# WBZ450 register map
Vendor: Microchip
Registers are 32-bit, read-write, reset 0x0 unless marked. A register's access mark holds for its fields unless they carry their own. Addresses are absolute, and some are shared; only a register's first bit layout is shown; [hi:lo] are bit positions; 'fields as' and 'values as' point back to an identical list.

## TC3
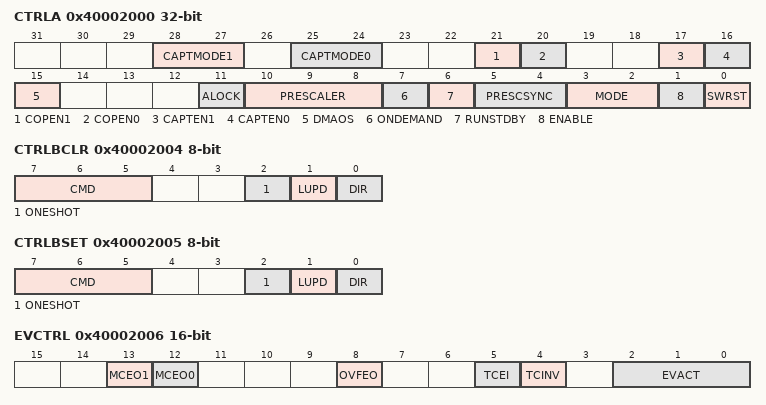
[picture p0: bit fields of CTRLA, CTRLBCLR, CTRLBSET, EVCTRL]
0x40002000 CTRLA
  [28:27] CAPTMODE1 — Capture mode Channel 1
    0=DEFAULT (Default capture); 1=CAPTMIN (Minimum capture); 2=CAPTMAX (Maximum capture)
  [25:24] CAPTMODE0 — Capture Mode Channel 0
    values as CAPTMODE1
  [21] COPEN1 — Capture On Pin 1 Enable
  [20] COPEN0 — Capture On Pin 0 Enable
  [17] CAPTEN1 — Capture Channel 1 Enable
  [16] CAPTEN0 — Capture Channel 0 Enable
  [15] DMAOS — DMA One Shot
  [11] ALOCK — Auto Lock
  [10:8] PRESCALER
    0=DIV1 (Prescaler: GCLK_TC); 1=DIV2 (Prescaler: GCLK_TC/2); 2=DIV4 (Prescaler: GCLK_TC/4); 3=DIV8 (Prescaler: GCLK_TC/8); 4=DIV16 (Prescaler: GCLK_TC/16); 5=DIV64 (Prescaler: GCLK_TC/64); 6=DIV256 (Prescaler: GCLK_TC/256); 7=DIV1024 (Prescaler: GCLK_TC/1024)
  [7] ONDEMAND — Clock On Demand
  [6] RUNSTDBY — Run during Standby
  [5:4] PRESCSYNC — Prescaler and Counter Synchronization
    0=GCLK (Reload or reset the counter on next generic clock); 1=PRESC (Reload or reset the counter on next prescaler clock); 2=RESYNC (Reload or reset the counter on next generic clock and reset the prescaler counter)
  [3:2] MODE — Timer Counter Mode
    0=COUNT16 (Counter in 16-bit mode); 1=COUNT8 (Counter in 8-bit mode); 2=COUNT32 (Counter in 32-bit mode)
  [1] ENABLE
  [0] SWRST — Software Reset
0x40002004 CTRLBCLR 8-bit
  [7:5] CMD — Command
    0=NONE (No action); 1=RETRIGGER (Force a start, restart or retrigger); 2=STOP (Force a stop); 3=UPDATE (Force update of double-buffered register); 4=READSYNC (Force a read synchronization of COUNT); 5=DMAOS (One-shot DMA trigger)
  [2] ONESHOT — One-Shot on Counter
  [1] LUPD — Lock Update
  [0] DIR — Counter Direction
0x40002005 CTRLBSET 8-bit
  fields as CTRLBCLR
0x40002006 EVCTRL 16-bit
  [13] MCEO1 — MC Event Output Enable 1
  [12] MCEO0 — MC Event Output Enable 0
  [8] OVFEO — Event Output Enable
  [5] TCEI — TC Event Enable
  [4] TCINV — TC Event Input Polarity
  [2:0] EVACT — Event Action
    0=OFF (Event action disabled); 1=RETRIGGER (Start, restart or retrigger TC on event); 2=COUNT (Count on event); 3=START (Start TC on event); 4=STAMP (Time stamp capture); 5=PPW (Period catured in CC0, pulse width in CC1); 6=PWP (Period catured in CC1, pulse width in CC0); 7=PW (Pulse width capture)
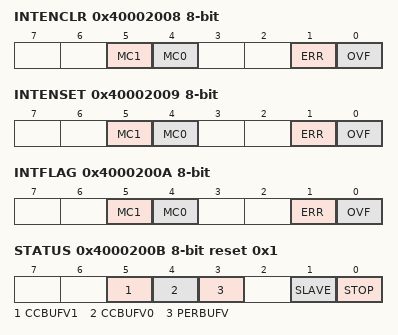
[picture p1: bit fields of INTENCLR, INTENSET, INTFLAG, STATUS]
0x40002008 INTENCLR 8-bit
  [5] MC1 — MC Interrupt Disable 1
  [4] MC0 — MC Interrupt Disable 0
  [1] ERR — ERR Interrupt Disable
  [0] OVF — OVF Interrupt Disable
0x40002009 INTENSET 8-bit
  [5] MC1 — MC Interrupt Enable 1
  [4] MC0 — MC Interrupt Enable 0
  [1] ERR — ERR Interrupt Enable
  [0] OVF — OVF Interrupt Enable
0x4000200A INTFLAG 8-bit
  [5] MC1 — MC Interrupt Flag 1
  [4] MC0 — MC Interrupt Flag 0
  [1] ERR — ERR Interrupt Flag
  [0] OVF — OVF Interrupt Flag
0x4000200B STATUS 8-bit reset 0x1
  [5] CCBUFV1 — Compare channel buffer 1 valid
  [4] CCBUFV0 — Compare channel buffer 0 valid
  [3] PERBUFV — Synchronization Busy Status
  [1] SLAVE — Slave Status Flag
  [0] STOP — Stop Status Flag
0x4000200C WAVE 8-bit
  [1:0] WAVEGEN — Waveform Generation Mode
    0=NFRQ (Normal frequency); 1=MFRQ (Match frequency); 2=NPWM (Normal PWM); 3=MPWM (Match PWM)
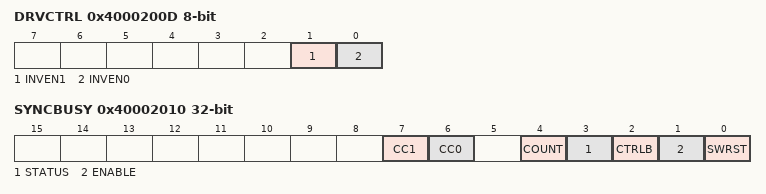
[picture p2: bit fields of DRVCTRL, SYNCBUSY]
0x4000200D DRVCTRL 8-bit
  [1] INVEN1 — Output Waveform Invert Enable 1
  [0] INVEN0 — Output Waveform Invert Enable 0
0x4000200F DBGCTRL 8-bit
  [0] DBGRUN — Run During Debug
0x40002010 SYNCBUSY ro
  [7] CC1 — Compare Channel 1
  [6] CC0 — Compare Channel 0
  [4] COUNT — Counter
  [3] STATUS
  [2] CTRLB
  [1] ENABLE
  [0] SWRST

## DSU
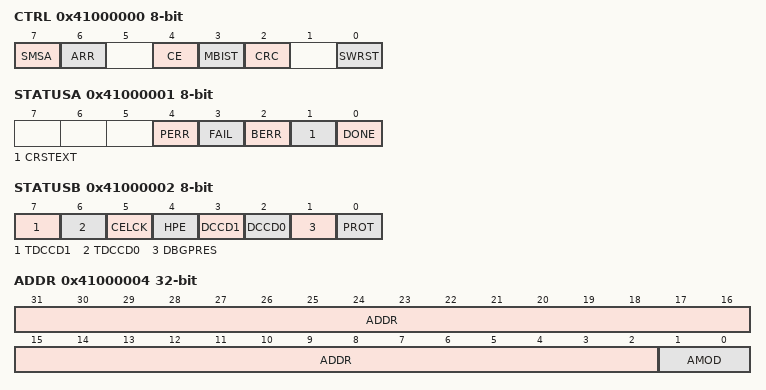
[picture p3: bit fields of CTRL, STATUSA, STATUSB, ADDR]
0x41000000 CTRL 8-bit wo
  [7] SMSA — Start Memory Stream Access
  [6] ARR — Auxiliary Row Read
  [4] CE — Chip-Erase
  [3] MBIST — Memory built-in self-test
  [2] CRC — 32-bit Cyclic Redundancy Code
  [0] SWRST — Software Reset
0x41000001 STATUSA 8-bit
  [4] PERR — Protection Error
  [3] FAIL — Failure
  [2] BERR — Bus Error
  [1] CRSTEXT — CPU Reset Phase Extension
  [0] DONE
0x41000002 STATUSB 8-bit ro
  [7] TDCCD1 — Test Debug Communication Channel 1 Dirty
  [6] TDCCD0 — Test Debug Communication Channel 0 Dirty
  [5] CELCK — Chip Erase Locked
  [4] HPE — Hot-Plugging Enable
  [3] DCCD1 — Debug Communication Channel 1 Dirty
  [2] DCCD0 — Debug Communication Channel 0 Dirty
  [1] DBGPRES — Debugger Present
  [0] PROT — Protected
0x41000004 ADDR
  [31:2] ADDR — Address
  [1:0] AMOD — Access Mode
0x41000008 LENGTH
  [31:2] LENGTH
0x4100000C DATA
0x41000010 DCC0
  [31:0] DATA
0x41000014 DCC1
  [31:0] DATA
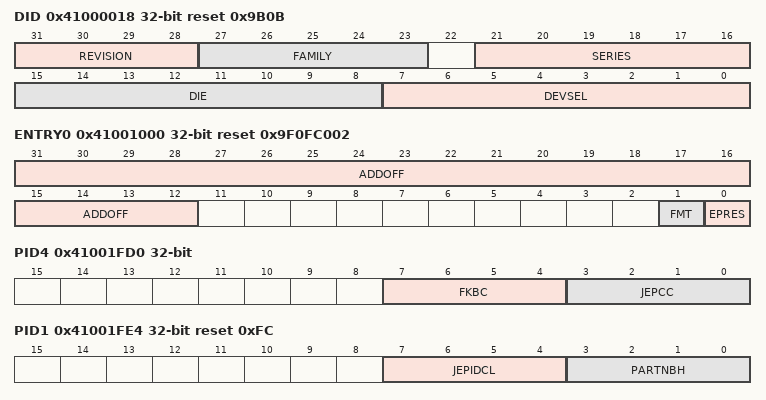
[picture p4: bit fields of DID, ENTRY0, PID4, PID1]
0x41000018 DID ro reset 0x9B0B
  [31:28] REVISION — Revision Number
  [27:23] FAMILY
    0=General purpose microcontroller; 1=PicoPower
  [21:16] SERIES
    0=Cortex-M0+ processor, basic feature set; 1=Cortex-M0+ processor, USB
  [15:8] DIE — Die Number
  [7:0] DEVSEL — Device Select
0x41001000 ENTRY0 ro reset 0x9F0FC002
  [31:12] ADDOFF — Address Offset
  [1] FMT — Format
  [0] EPRES — Entry Present
0x41001004 ENTRY1 ro
0x41001008 END ro
  [31:0] END — End Marker
0x41001FCC MEMTYPE ro
  [0] SMEMP — System Memory Present
0x41001FD0 PID4 ro
  [7:4] FKBC — 4KB count
  [3:0] JEPCC — JEP-106 Continuation Code
0x41001FE0 PID0 ro reset 0xD0
  [7:0] PARTNBL — Part Number Low
0x41001FE4 PID1 ro reset 0xFC
  [7:4] JEPIDCL — Low part of the JEP-106 Identity Code
  [3:0] PARTNBH — Part Number High
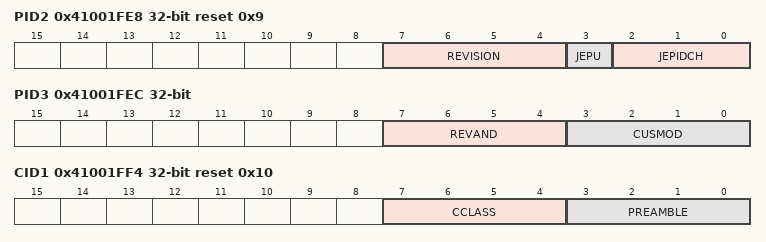
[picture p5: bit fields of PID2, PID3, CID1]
0x41001FE8 PID2 ro reset 0x9
  [7:4] REVISION — Revision Number
  [3] JEPU — JEP-106 Identity Code is used
  [2:0] JEPIDCH — JEP-106 Identity Code High
0x41001FEC PID3 ro
  [7:4] REVAND — Revision Number
  [3:0] CUSMOD — ARM CUSMOD
0x41001FF0 CID0 ro reset 0xD
  [7:0] PREAMBLEB0 — Preamble Byte 0
0x41001FF4 CID1 ro reset 0x10
  [7:4] CCLASS — Component Class
  [3:0] PREAMBLE
0x41001FF8 CID2 ro reset 0x5
  [7:0] PREAMBLEB2 — Preamble Byte 2
0x41001FFC CID3 ro reset 0xB1
  [7:0] PREAMBLEB3 — Preamble Byte 3
